# RN831X_RN861X_MCU register map
File version: v0.0.1
CPU: RN831X_RN861X_MCU r1p0, little endian, MPU, no FPU
Registers are 32-bit, read-write, reset 0x0 unless marked. A register's access mark holds for its fields unless they carry their own. Offsets are from the block's base; [hi:lo] are bit positions; {n}, {i} and the like mark numbered series.

## IOCNT_CORE0 — IOCNT Module core0
Base 0x2005C000
Same registers: IOCNT_CORE1 0xA005C000
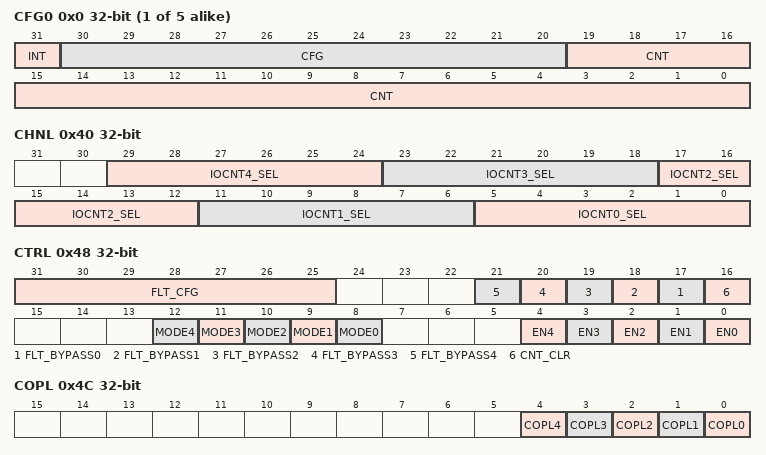
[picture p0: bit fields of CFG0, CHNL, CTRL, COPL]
{0x0+4i} CFG{i} access per field (i=0..4) — IOCNT{i} configuration register
  [31] INT rw — Pulse invert enable bit
    0=NORM (Output pulse level direction follow with input pulse level); 1=INT (Invert output pulse level)
  [30:20] CFG rw — Pulse prescale confige bit
  [19:0] CNT ro — Input pulse counter
{0x20+4i} OUT{i} access not given (i=0..4) — IOCNT{i} output pulse counter register
  [19:0] CNT — IOCNT{i} output pulse counter bits
0x40 CHNL — IOCNTx input channel select register
  [6n+5:6n] IOCNT{n}_SEL (n=0..4) — Input data type select bit of IOCNT{n}
0x48 CTRL — IOCNTx Control register
  [31:25] FLT_CFG — IOCNT4~IOCNT0 filter cycle configuration
  [n+17] FLT_BYPASS{n} (n=0..4) — Filter bypass of IOCNT{n}
  [16] CNT_CLR — Pulse counter read to clear confige bit
    0=R2CLR (Read to clear type); 1=COUNT (Continue to count after read)
  [n+8] MODE{n} (n=0..4) — IOCNT{n} pulse counter mode
    0=RISEEDGE (Rising edge triggered); 1=FALLEDGE (Falling edge triggered)
  [n] EN{n} (n=0..4) — IOCNT{n} enable bit
0x4C COPL — IOCNTx output pulse configuration register
  [all] fields
    0=Output the (n+1)th pulse at the (n*CNT+1)th input pulse; 1=Output the (n)th pulse at the (n*CNT)th input pulse
  [n] COPL{n} (n=0..4) — IOCNT{n} output pulse confige bit
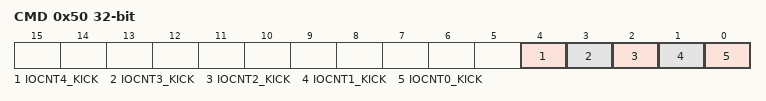
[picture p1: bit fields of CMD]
0x50 CMD wo — IOCNTx input command register
  [4] IOCNT4_KICK — IOCNT4 software pulse trigger bit
  [3] IOCNT3_KICK — IOCNT5 software pulse trigger bit
  [2] IOCNT2_KICK — IOCNT6 software pulse trigger bit
  [1] IOCNT1_KICK — IOCNT7 software pulse trigger bit
  [0] IOCNT0_KICK — IOCNT8 software pulse trigger bit
{0x60+4i} REMD{i} access not given (i=0..4) — IOCNT{i} input pulse remainder register
  [10:0] REMD{i} — IOCNT{i} input pulse remainder bits

## ISO78160_CORE0 — ISO78160 Module core0
Base 0x20030000
Same registers: ISO78161_CORE0 0x20034000, ISO78160_CORE1 0xA0030000, ISO78161_CORE1 0xA0034000
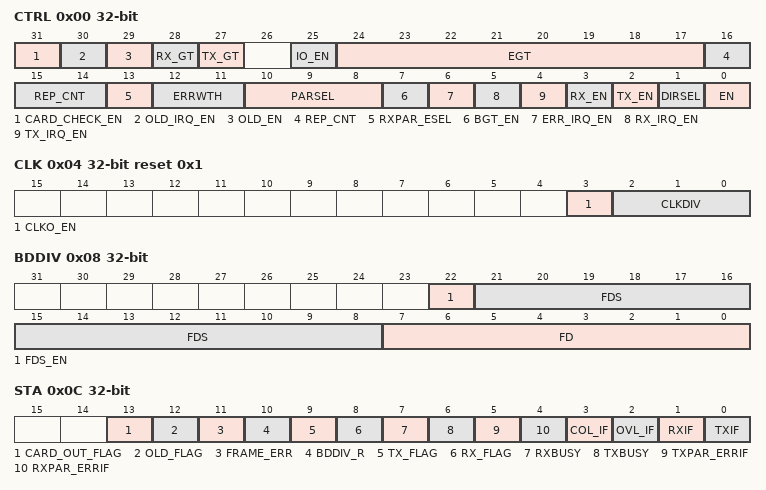
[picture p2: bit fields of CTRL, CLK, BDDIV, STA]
0x00 CTRL — Control Register
  [31] CARD_CHECK_EN — Card pull-out detection enable, Only valid when OLD detection function is enabled
  [30] OLD_IRQ_EN — OLD Detection interrupt enable
  [29] OLD_EN — OLD detection function enable
  [28] RX_GT — Receive data GT width selection
  [27] TX_GT — Send data GT width selection
  [25] IO_EN — Data bidirectional enable
  [24:17] EGT — EGT width selection value (0~255), additional protection time N
  [16:14] REP_CNT — Automatic retransmission times when data parity check error occurs
    0=NONE (No automatic retransmission); {v}=Automatic retransmission count is {v} (v=1..7)
  [13] RXPAR_ESEL — Receive data parity check error handling methods selection, enable error signal (NACK) transmission when data check error
  [12:11] ERRWTH — Error signal width selection
    0=Error signal width 2 ETU selected; 1=Error signal width 1 ETU selected; 2=1_5 (Error signal width 1.5 ETU selected)
  [10:8] PARSEL — Parity selection, configure Parity
    0=PARITY_NONE (No parity); 1=PARITY_ODD (Odd parity is selected); 2=PARITY_EVEN (Even parity is selected); 3=PARITY_ZERO (Fixed zero parity is selected); 4=PARITY_ONE (Fixed one parity is selected); 5=PARITY_USER_DEFINED (User defined parity is selected,)
  [7] BGT_EN — Data received and sent BGT control
  [6] ERR_IRQ_EN — Transfer error interrupt enable
  [5] RX_IRQ_EN — Receive interrupt enable
  [4] TX_IRQ_EN — Transmit interrupt enable
  [3] RX_EN — Receive data enable
  [2] TX_EN — Transmit data enable
  [1] DIRSEL — Data encoding method selection
  [0] EN — Controller enable
0x04 CLK reset 0x1 — Clock Configuration Register
  [3] CLKO_EN — Card clock output enable
  [2:0] CLKDIV — Clock output division coefficient selection
    0=Frequency division coefficient is 0; 1=Frequency division coefficient is 2; 2=Frequency division coefficient is 4; 3=Frequency division coefficient is 8; 4=Frequency division coefficient is 16; 5=Frequency division coefficient is 32
0x08 BDDIV — Baudrate coefficients Register
  [22] FDS_EN — Software configuration of F/D
  [21:8] FDS — Configured by software, can only be written when FDS_EN = 1, in other cases, it is 14d'372
  [7:0] FD — This 8 bits FI(b4-b7) and DI(b0-b3) transmitted by Answer To Resest (ATR), the configuration information is shown in table
0x0C STA access per field — Status Indicator Register
  [13] CARD_OUT_FLAG rw write-1-clears — Card pull-out detect flag, it is valid after CARD_CHECK_EN is enabled
  [12] OLD_FLAG rw write-1-clears — Receive OLD signal interrupt flag, it is valid after OLD_EN is enabled
  [11] FRAME_ERR rw write-1-clears — Receive data frame format error interrupt flag
  [10] BDDIV_R ro — Baud rate match indication bit, read only
  [9] TX_FLAG ro — Send buffer empty flag, read only
  [8] RX_FLAG ro — Data receiving complete flag, read only
  [7] RXBUSY ro — Data receiving busy flag, read only
  [6] TXBUSY ro — Data sending busy flag, read only
  [5] TXPAR_ERRIF rw write-1-clears — Transmit data parity error flag
  [4] RXPAR_ERRIF rw write-1-clears — Receive data parity error flag
  [3] COL_IF rw write-1-clears — Transmit data conflict error interrupt flag
  [2] OVL_IF rw write-1-clears — Receive data overflow interrupt flag
  [1] RXIF rw write-1-clears — Data received interrupt flag
  [0] TXIF rw write-1-clears — Data transmit interrupt flag
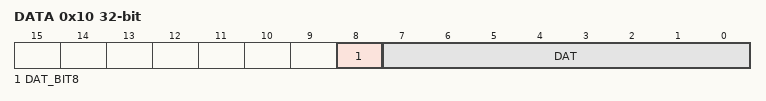
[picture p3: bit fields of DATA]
0x10 DATA — Transceiver Register
  [8] DAT_BIT8 — When parsel is in user defined mode, this data bit is parity
  [7:0] DAT — Data register
